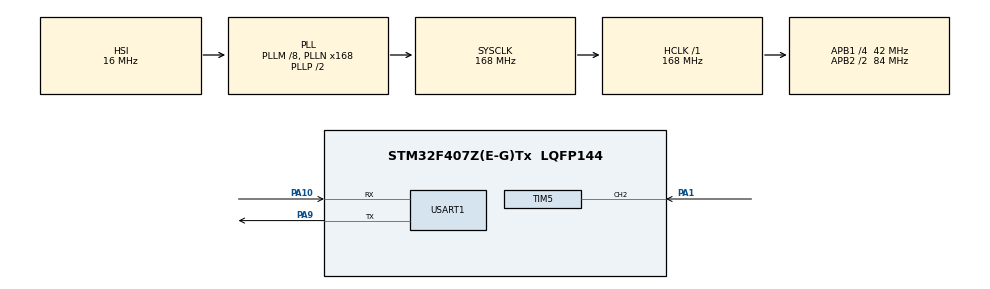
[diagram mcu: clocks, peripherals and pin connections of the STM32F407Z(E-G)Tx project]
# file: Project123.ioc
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Mcu.Family=STM32F4
Dma.USART1_TX.1.Instance=DMA2_Stream7
PH0-OSC_IN.Signal=RCC_OSC_IN
RCC.CortexFreq_Value=168000000
Dma.USART1_RX.0.PeriphDataAlignment=DMA_PDATAALIGN_BYTE
PA10.Mode=Asynchronous
Dma.USART1_TX.1.MemInc=DMA_MINC_ENABLE
SH.S_TIM5_CH2.0=TIM5_CH2,Input_Capture2_from_TI2
RCC.APB1CLKDivider=RCC_HCLK_DIV4
RCC.SYSCLKSource=RCC_SYSCLKSOURCE_PLLCLK
ProjectManager.StackSize=0x400
TIM5.Channel-Input_Capture2_from_TI2=TIM_CHANNEL_2
PA13.Signal=SYS_JTMS-SWDIO
PA9.Mode=Asynchronous
ProjectManager.TargetToolchain=STM32CubeIDE
NVIC.TIM5_IRQn=true\:0\:0\:false\:false\:true\:true\:true
RCC.HCLKFreq_Value=168000000
Dma.USART1_RX.0.Direction=DMA_PERIPH_TO_MEMORY
RCC.APB2TimFreq_Value=168000000
PA9.Signal=USART1_TX
Dma.USART1_TX.1.FIFOMode=DMA_FIFOMODE_DISABLE
RCC.LSE_VALUE=32768
PA1.Signal=S_TIM5_CH2
RCC.AHBFreq_Value=168000000
PH0-OSC_IN.Mode=HSE-External-Oscillator
Dma.USART1_RX.0.PeriphInc=DMA_PINC_DISABLE
Dma.USART1_RX.0.Priority=DMA_PRIORITY_LOW
RCC.HSE_VALUE=25000000
Dma.USART1_TX.1.MemDataAlignment=DMA_MDATAALIGN_BYTE
board=custom
RCC.VCOOutputFreq_Value=336000000
RCC.APB2Freq_Value=84000000
PA14.Mode=Serial_Wire
PH1-OSC_OUT.Signal=RCC_OSC_OUT
Dma.USART1_RX.0.MemDataAlignment=DMA_MDATAALIGN_BYTE
Dma.USART1_RX.0.MemInc=DMA_MINC_ENABLE
PA13.Mode=Serial_Wire
Mcu.Name=STM32F407Z(E-G)Tx
Dma.USART1_TX.1.PeriphDataAlignment=DMA_PDATAALIGN_BYTE
PH1-OSC_OUT.Mode=HSE-External-Oscillator
RCC.48MHZClocksFreq_Value=84000000
RCC.SYSCLKFreq_VALUE=168000000
Mcu.Package=LQFP144
NVIC.DMA2_Stream7_IRQn=true\:0\:0\:false\:false\:true\:false\:true
Dma.USART1_TX.1.Mode=DMA_NORMAL
USART1.VirtualMode=VM_ASYNC
PA10.Signal=USART1_RX
PA14.Signal=SYS_JTCK-SWCLK
ProjectManager.HeapSize=0x200
Dma.USART1_TX.1.PeriphInc=DMA_PINC_DISABLE
RCC.HSI_VALUE=16000000
NVIC.PriorityGroup=NVIC_PRIORITYGROUP_4
Dma.USART1_RX.0.FIFOMode=DMA_FIFOMODE_DISABLE
RCC.APB2CLKDivider=RCC_HCLK_DIV2
NVIC.DMA2_Stream2_IRQn=true\:0\:0\:false\:false\:true\:false\:true
RCC.PLLM=8
RCC.PLLN=168
Dma.Request1=USART1_TX
RCC.APB1TimFreq_Value=84000000
Dma.USART1_RX.0.Mode=DMA_NORMAL
TIM5.Period=0xffffffff
Dma.USART1_TX.1.Priority=DMA_PRIORITY_LOW
NVIC.USART1_IRQn=true\:0\:0\:false\:false\:true\:true\:true
RCC.APB1Freq_Value=42000000
Dma.Request0=USART1_RX
Dma.USART1_RX.0.Instance=DMA2_Stream2
Dma.USART1_TX.1.Direction=DMA_MEMORY_TO_PERIPH

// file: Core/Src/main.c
/* USER CODE BEGIN Header */
/**
  ******************************************************************************
  * @file           : main.c
  * @brief          : Main program body
  ******************************************************************************
  * @attention
  *
  * <h2><center>&copy; Copyright (c) 2021 STMicroelectronics.
  * All rights reserved.</center></h2>
  *
  * This software component is licensed by ST under BSD 3-Clause license,
  * the "License"; You may not use this file except in compliance with the
  * License. You may obtain a copy of the License at:
  *                        opensource.org/licenses/BSD-3-Clause
  *
  ******************************************************************************
  */
/* USER CODE END Header */
#include "main.h"
#include "dma.h"
#include "tim.h"
#include "usart.h"
#include "gpio.h"

/* USER CODE BEGIN Includes */
#include "stdio.h"
/* USER CODE END Includes */

void SystemClock_Config(void);

/* USER CODE BEGIN 0 */
uint32_t capture_Buf[3] = {0};   //存放计数值
uint8_t capture_Cnt = 0;    //状态标志位
uint32_t high_time;   //高电平时间
uint32_t low_time;

uint32_t high_time1[10] = {0};   //高电平时间
uint32_t low_time1[10] = {0};
uint32_t period_time1[10] = {0};
uint32_t frequency[10] = {0};

uint32_t capture_Buf2[10][3] = {0};

uint32_t frequent_avg = 0;

int i;

/* USER CODE END 0 */

int main(void)
{

  /* MCU Configuration--------------------------------------------------------*/

  /* Reset of all peripherals, Initializes the Flash interface and the Systick. */
  HAL_Init();

  /* Configure the system clock */
  SystemClock_Config();

  /* Initialize all configured peripherals */
  MX_GPIO_Init();
  MX_DMA_Init();
  MX_TIM5_Init();
  MX_USART1_UART_Init();

  /* Infinite loop */
  while (1)
  {

    /* USER CODE BEGIN 3 */
    for(i = 0; i < 10; ) {
        switch (capture_Cnt) {
            case 0:
                capture_Cnt++;
                __HAL_TIM_SET_CAPTUREPOLARITY(&htim5, TIM_CHANNEL_1, TIM_INPUTCHANNELPOLARITY_RISING);
                HAL_TIM_IC_Start_IT(&htim5, TIM_CHANNEL_1);    //启动输入捕获       或者: __HAL_TIM_ENABLE(&htim5);
                break;
            case 4:
                high_time1[i] = capture_Buf2[i][1] - capture_Buf2[i][0];    //高电平时间
                low_time1[i] = capture_Buf2[i][2] - capture_Buf2[i][1];    //低电平时间
                period_time1[i] = high_time1[i] + low_time1[i];
                frequency[i] = 84000000/period_time1[i];
                int ht = high_time1[i];
                int lt = low_time1[i];
                int t = ht + lt;
                int f = 84000000 / t;
                __HAL_TIM_SET_CAPTUREPOLARITY(&htim5, TIM_CHANNEL_1, TIM_INPUTCHANNELPOLARITY_RISING);
                //HAL_Delay(1000);   //延时1S
                capture_Cnt = 0;  //清空标志位
                i++;
                break;
        }
    }
    frequent_avg = 0;
      for (int j = 0; j < 10; j++) {
          frequent_avg += frequency[j];
      }
      frequent_avg /= 10;
    HAL_Delay(1000);
  }
  HAL_Delay(1000);
  /* USER CODE END 3 */
}

void SystemClock_Config(void)
{
  RCC_OscInitTypeDef RCC_OscInitStruct = {0};
  RCC_ClkInitTypeDef RCC_ClkInitStruct = {0};

  /** Configure the main internal regulator output voltage
  */
  __HAL_RCC_PWR_CLK_ENABLE();
  __HAL_PWR_VOLTAGESCALING_CONFIG(PWR_REGULATOR_VOLTAGE_SCALE1);
  /** Initializes the RCC Oscillators according to the specified parameters
  * in the RCC_OscInitTypeDef structure.
  */
  RCC_OscInitStruct.OscillatorType = RCC_OSCILLATORTYPE_HSI;
  RCC_OscInitStruct.HSIState = RCC_HSI_ON;
  RCC_OscInitStruct.HSICalibrationValue = RCC_HSICALIBRATION_DEFAULT;
  RCC_OscInitStruct.PLL.PLLState = RCC_PLL_ON;
  RCC_OscInitStruct.PLL.PLLSource = RCC_PLLSOURCE_HSI;
  RCC_OscInitStruct.PLL.PLLM = 8;
  RCC_OscInitStruct.PLL.PLLN = 168;
  RCC_OscInitStruct.PLL.PLLP = RCC_PLLP_DIV2;
  RCC_OscInitStruct.PLL.PLLQ = 4;
  if (HAL_RCC_OscConfig(&RCC_OscInitStruct) != HAL_OK)
  {
    Error_Handler();
  }
  /** Initializes the CPU, AHB and APB buses clocks
  */
  RCC_ClkInitStruct.ClockType = RCC_CLOCKTYPE_HCLK|RCC_CLOCKTYPE_SYSCLK
                              |RCC_CLOCKTYPE_PCLK1|RCC_CLOCKTYPE_PCLK2;
  RCC_ClkInitStruct.SYSCLKSource = RCC_SYSCLKSOURCE_PLLCLK;
  RCC_ClkInitStruct.AHBCLKDivider = RCC_SYSCLK_DIV1;
  RCC_ClkInitStruct.APB1CLKDivider = RCC_HCLK_DIV4;
  RCC_ClkInitStruct.APB2CLKDivider = RCC_HCLK_DIV2;

  if (HAL_RCC_ClockConfig(&RCC_ClkInitStruct, FLASH_LATENCY_5) != HAL_OK)
  {
    Error_Handler();
  }
}

void Error_Handler(void)
{
  __disable_irq();
  while (1)
  {
  }
}

/************************ (C) COPYRIGHT STMicroelectronics *****END OF FILE****/
